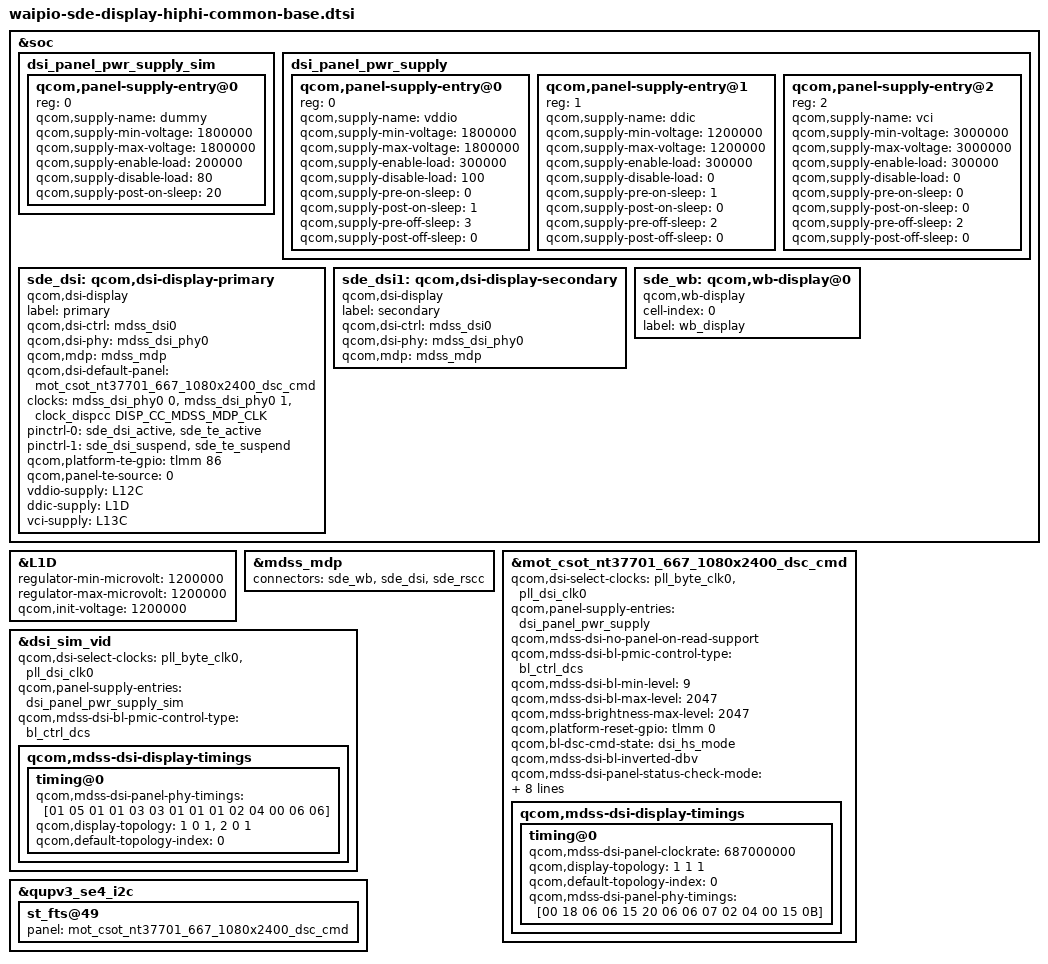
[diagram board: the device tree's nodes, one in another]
/*
   this is original from waipio-sde-display-hiphi-common-base.dtsi
*/
#include "waipio-sde-display-pinctrl.dtsi"
#include "dsi-panel-sim-video.dtsi"
#include <dt-bindings/clock/qcom,dispcc-waipio.h>
#include "dsi-panel-mot-csot-nt37701-667-1080x2400-dsc-cmd-common.dtsi"

&soc {
	dsi_panel_pwr_supply_sim: dsi_panel_pwr_supply_sim {
		#address-cells = <1>;
		#size-cells = <0>;

		qcom,panel-supply-entry@0 {
			reg = <0>;
			qcom,supply-name = "dummy";
			qcom,supply-min-voltage = <1800000>;
			qcom,supply-max-voltage = <1800000>;
			qcom,supply-enable-load = <200000>;
			qcom,supply-disable-load = <80>;
			qcom,supply-post-on-sleep = <20>;
		};
	};

	dsi_panel_pwr_supply: dsi_panel_pwr_supply {
		#address-cells = <1>;
		#size-cells = <0>;

	qcom,panel-supply-entry@0 {
		reg = <0>;
		qcom,supply-name = "vddio";
		qcom,supply-min-voltage = <1800000>;
		qcom,supply-max-voltage = <1800000>;
		qcom,supply-enable-load = <300000>;
		qcom,supply-disable-load = <100>;
		qcom,supply-pre-on-sleep = <0>;
		qcom,supply-post-on-sleep = <1>;
		qcom,supply-pre-off-sleep = <3>;
		qcom,supply-post-off-sleep = <0>;
        };

        qcom,panel-supply-entry@1 {
		reg = <1>;
		qcom,supply-name = "ddic";
		qcom,supply-min-voltage = <1200000>;
		qcom,supply-max-voltage = <1200000>;
		qcom,supply-enable-load = <300000>;
		qcom,supply-disable-load = <0>;
		qcom,supply-pre-on-sleep = <1>;
		qcom,supply-post-on-sleep = <0>;
		qcom,supply-pre-off-sleep = <2>;
		qcom,supply-post-off-sleep = <0>;
        };
        qcom,panel-supply-entry@2 {
		reg = <2>;
		qcom,supply-name = "vci";
		qcom,supply-min-voltage = <3000000>;
		qcom,supply-max-voltage = <3000000>;
		qcom,supply-enable-load = <300000>;
		qcom,supply-disable-load = <0>;
		qcom,supply-pre-on-sleep = <0>;
		qcom,supply-post-on-sleep = <0>;
		qcom,supply-pre-off-sleep = <2>;
		qcom,supply-post-off-sleep = <0>;
        };
	};

	sde_dsi: qcom,dsi-display-primary {
		compatible = "qcom,dsi-display";
		label = "primary";

		qcom,dsi-ctrl = <&mdss_dsi0>;
		qcom,dsi-phy = <&mdss_dsi_phy0>;

		qcom,mdp = <&mdss_mdp>;
		qcom,dsi-default-panel = <&mot_csot_nt37701_667_1080x2400_dsc_cmd>;
	};

	sde_dsi1: qcom,dsi-display-secondary {
		compatible = "qcom,dsi-display";
		label = "secondary";

		qcom,dsi-ctrl = <&mdss_dsi0>;
		qcom,dsi-phy = <&mdss_dsi_phy0>;
		qcom,mdp = <&mdss_mdp>;
	};
};


&soc {
	/*display_panel_avdd: display_gpio_regulator@1 {
		compatible = "qti-regulator-fixed";
		regulator-name = "display_panel_avdd";
		regulator-min-microvolt = <5500000>;
		regulator-max-microvolt = <5500000>;
		regulator-enable-ramp-delay = <233>;
		gpio = <&tlmm 64 0>;
		enable-active-high;
		regulator-boot-on;
		proxy-supply = <&display_panel_avdd>;
		qcom,proxy-consumer-enable;
		pinctrl-names = "default";
		pinctrl-0 = <&display_panel_avdd_default>;
	};*/

	sde_wb: qcom,wb-display@0 {
		compatible = "qcom,wb-display";
		cell-index = <0>;
		label = "wb_display";
	};
};

&sde_dsi {
	clocks = <&mdss_dsi_phy0 0>,
			<&mdss_dsi_phy0 1>,

			 /*
			  * Currently the dsi clock handles are under the dsi
			  * controller DT node. As soon as the controller probe
			  * finishes, the dispcc sync state can get called before
			  * the dsi_display probe potentially disturbing the clock
			  * votes for cont_splash use case. Hence we are no longer
			  * protected by the component model in this case against the
			  * disp cc sync state getting triggered after the dsi_ctrl
			  * probe. To protect against this incorrect sync state trigger
			  * add this dummy MDP clk vote handle to the dsi_display
			  * DT node. Since the dsi_display driver does not parse
			  * MDP clock nodes, no actual vote shall be added and this
			  * change is done just to satisfy sync state requirements.
			  */
			 <&clock_dispcc DISP_CC_MDSS_MDP_CLK>;
	clock-names = "pll_byte_clk0", "pll_dsi_clk0",
			"mdp_core_clk";

	pinctrl-names = "panel_active", "panel_suspend";
	pinctrl-0 = <&sde_dsi_active &sde_te_active>;
	pinctrl-1 = <&sde_dsi_suspend &sde_te_suspend>;

	qcom,platform-te-gpio = <&tlmm 86 0>;
	qcom,panel-te-source = <0>;

	vddio-supply = <&L12C>;
	ddic-supply = <&L1D>;
	vci-supply = <&L13C>;
};

&L1D {
	regulator-min-microvolt = <1200000>;
	regulator-max-microvolt = <1200000>;
	qcom,init-voltage = <1200000>;
};

&mdss_mdp {
	connectors = <&sde_wb &sde_dsi &sde_rscc>;
};


&mot_csot_nt37701_667_1080x2400_dsc_cmd {
	qcom,dsi-select-clocks = "pll_byte_clk0", "pll_dsi_clk0";
	//qcom,dsi-select-sec-clocks = "pll_byte_clk1", "pll_dsi_clk1";

	//qcom,dsi-dyn-clk-enable;

	qcom,panel-supply-entries = <&dsi_panel_pwr_supply>;
	qcom,mdss-dsi-no-panel-on-read-support;
	qcom,mdss-dsi-bl-pmic-control-type = "bl_ctrl_dcs";
	qcom,mdss-dsi-bl-min-level = <9>;
	qcom,mdss-dsi-bl-max-level = <2047>;
	//qcom,mdss-dsi-bl-default-level = <1024>;
	qcom,mdss-brightness-max-level = <2047>;
	qcom,platform-reset-gpio = <&tlmm 0 0>;
	qcom,bl-dsc-cmd-state = "dsi_hs_mode";
	qcom,mdss-dsi-bl-inverted-dbv;

	qcom,mdss-dsi-panel-status-check-mode = "reg_read";
	qcom,mdss-dsi-panel-status-command = [06 01 00 01 00 00 01 0a];
	qcom,mdss-dsi-panel-status-command-state = "dsi_lp_mode";
	qcom,mdss-dsi-panel-status-value = <0x9c>;
	qcom,mdss-dsi-panel-status-read-length = <1>;
	qcom,esd-check-enabled;

	qcom,mdss-dsi-display-timings {
		timing@0 {
			qcom,mdss-dsi-panel-clockrate = <687000000>;
			qcom,display-topology = <1 1 1>;
			qcom,default-topology-index = <0>;
			qcom,mdss-dsi-panel-phy-timings = [00 18 06 06 15 20 06
							06 07 02 04 00 15 0B];
		};
	};
};

&dsi_sim_vid {
	qcom,dsi-select-clocks = "pll_byte_clk0", "pll_dsi_clk0";
	qcom,panel-supply-entries = <&dsi_panel_pwr_supply_sim>;
	qcom,mdss-dsi-bl-pmic-control-type = "bl_ctrl_dcs";
	qcom,mdss-dsi-display-timings {
		timing@0 {
			qcom,mdss-dsi-panel-phy-timings = [01 05 01 01 03 03 01
				01 01 02 04 00 06 06];
			qcom,display-topology = <1 0 1>,
						<2 0 1>;
			qcom,default-topology-index = <0>;
		};
	};
};

&sde_dsi {
	qcom,dsi-default-panel = <&mot_csot_nt37701_667_1080x2400_dsc_cmd>;
};

&qupv3_se4_i2c {
	st_fts@49 {
		panel = <&mot_csot_nt37701_667_1080x2400_dsc_cmd>;
	};
};
